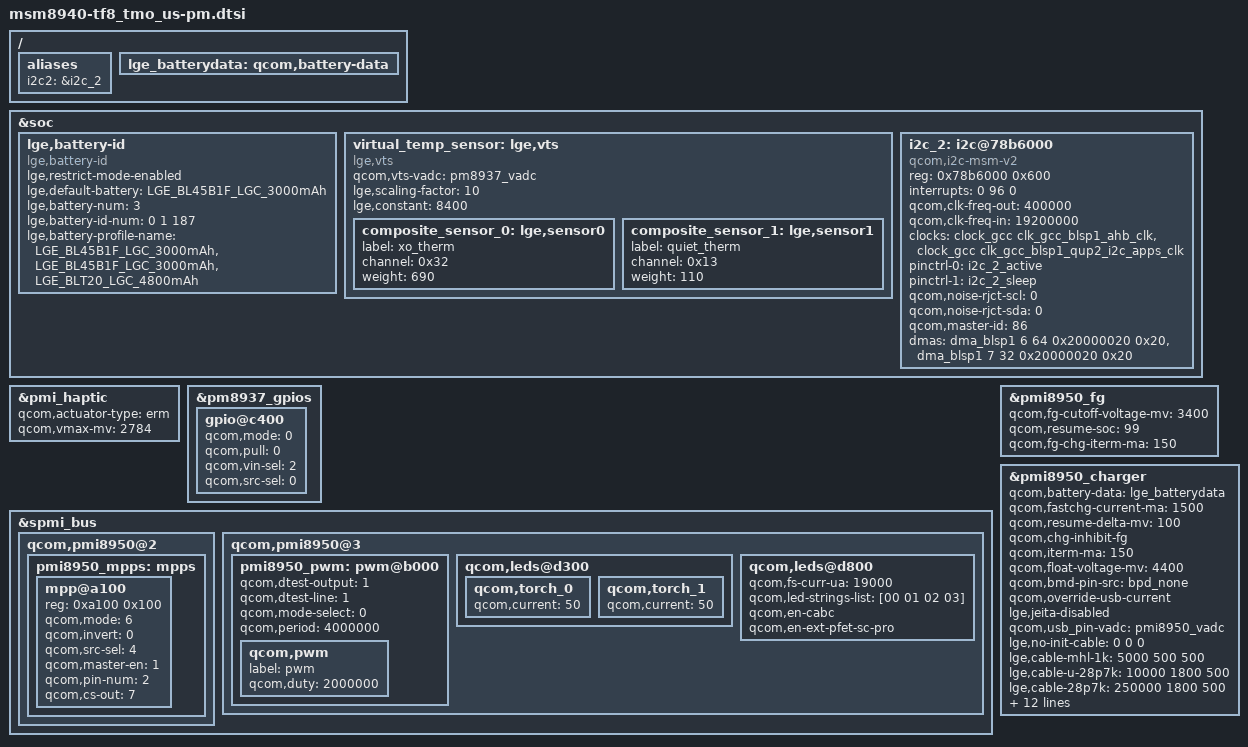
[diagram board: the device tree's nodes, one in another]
/*
 * Copyright (c) 2016, The Linux Foundation. All rights reserved.
 *
 * This program is free software; you can redistribute it and/or modify
 * it under the terms of the GNU General Public License version 2 and
 * only version 2 as published by the Free Software Foundation.
 *
 * This program is distributed in the hope that it will be useful,
 * but WITHOUT ANY WARRANTY; without even the implied warranty of
 * MERCHANTABILITY or FITNESS FOR A PARTICULAR PURPOSE.  See the
 * GNU General Public License for more details.
 */

/ {
	aliases {
		i2c2 = &i2c_2;
	};
};

/{
    lge_batterydata: qcom,battery-data {
         #include "../battery_profile/LGE_BL45B1F_LGC_3000mAh.dtsi"
         #include "../battery_profile/LGE_BLT20_LGC_4800mAh.dtsi"

    };
};

&soc {
	lge,battery-id{
		compatible = "lge,battery-id";
		lge,restrict-mode-enabled;
		/*default battery profile*/
		lge,default-battery = "LGE_BL45B1F_LGC_3000mAh";
		/*Total number of combined of battery cell and battery id */
		lge,battery-num = <3>;
		/* battery id and battery profile match numbers */
		lge,battery-id-num = <0 1 187>;
		/* battery profile */
		lge,battery-profile-name = 	"LGE_BL45B1F_LGC_3000mAh",
						"LGE_BL45B1F_LGC_3000mAh",
						"LGE_BLT20_LGC_4800mAh";
	};

	/* vst = (0.42*xo_therm) + (0.44*quiet_therm) + 4.6 */
	virtual_temp_sensor: lge,vts {
		compatible = "lge,vts";
		qcom,vts-vadc = <&pm8937_vadc>;
		lge,scaling-factor= <10>;
		lge,constant = <8400>;
		composite_sensor_0: lge,sensor0 {
			label = "xo_therm";
			channel = <0x32>;
			weight = <690>;
		};
		composite_sensor_1: lge,sensor1 {
			label = "quiet_therm";
			channel = <0x13>;
			weight = <110>;
		};
	};

	i2c_2: i2c@78b6000 { /* BLSP1 QUP2 */
		compatible = "qcom,i2c-msm-v2";
		#address-cells = <1>;
		#size-cells = <0>;
		reg-names = "qup_phys_addr";
		reg = <0x78b6000 0x600>;
		interrupt-names = "qup_irq";
		interrupts = <0 96 0>;
		qcom,clk-freq-out = <400000>;
		qcom,clk-freq-in  = <19200000>;
		clock-names = "iface_clk", "core_clk";
		clocks = <&clock_gcc clk_gcc_blsp1_ahb_clk>,
			 <&clock_gcc clk_gcc_blsp1_qup2_i2c_apps_clk>;

		pinctrl-names = "i2c_active", "i2c_sleep";
		pinctrl-0 = <&i2c_2_active>;
		pinctrl-1 = <&i2c_2_sleep>;
		qcom,noise-rjct-scl = <0>;
		qcom,noise-rjct-sda = <0>;
		qcom,master-id = <86>;
		dmas = <&dma_blsp1 6 64 0x20000020 0x20>,
			<&dma_blsp1 7 32 0x20000020 0x20>;
		dma-names = "tx", "rx";
	};
};

&pmi_haptic{
	status = "okay";
	qcom,actuator-type = "erm";
	qcom,vmax-mv = <2784>;
};

&pm8937_gpios {
	gpio@c400 {
		qcom,mode = <0>;
		qcom,pull = <0>;
		qcom,vin-sel = <2>;
		qcom,src-sel = <0>;
		status = "okay";
	};
};

&spmi_bus {
	qcom,pmi8950@2 {
		pmi8950_mpps: mpps {
			mpp@a100 {
				status = "okay";
				reg = <0xa100 0x100>;
				qcom,mode = <6>;
				qcom,invert = <0>;
				qcom,src-sel = <4>;
				qcom,master-en = <1>;
				qcom,pin-num = <2>;
				qcom,cs-out = <7>;
			};
		};
	};

	qcom,pmi8950@3 {
		pmi8950_pwm: pwm@b000 {
			status = "ok";
			qcom,dtest-output = <1>;
			qcom,dtest-line = <1>;
			qcom,mode-select = <0>;
			qcom,period = <4000000>;
			qcom,pwm {
				label = "pwm";
				qcom,duty = <2000000>;
			};
		};
		qcom,leds@d300 {
			qcom,torch_0 {
				qcom,current = <50>;
			};
			qcom,torch_1 {
				qcom,current = <50>;
			};
		};
		qcom,leds@d800 {
			qcom,fs-curr-ua = <19000>;
			qcom,led-strings-list = [00 01 02 03];
			qcom,en-cabc;
			qcom,en-ext-pfet-sc-pro;
		};
	};
};

&pmi8950_fg {
	qcom,fg-cutoff-voltage-mv = <3400>;
	qcom,resume-soc = <99>;
	qcom,fg-chg-iterm-ma = <150>;
};

&pmi8950_charger {
	qcom,battery-data = <&lge_batterydata>;
	qcom,fastchg-current-ma = <1500>;
	qcom,resume-delta-mv = <100>;
	qcom,chg-inhibit-fg;
	qcom,iterm-ma = <150>;
	qcom,float-voltage-mv = <4400>;
	qcom,bmd-pin-src = "bpd_none";
	qcom,override-usb-current;
	lge,jeita-disabled;

	qcom,usb_pin-vadc = <&pmi8950_vadc>;

	/* ref resistance 200K */
	lge,no-init-cable = <0 0 0>;
	lge,cable-mhl-1k = <5000 500 500>;
	lge,cable-u-28p7k = <10000 1800 500>;
	lge,cable-28p7k = <250000 1800 500>;
	lge,cable-56k = <600000 1800 1500>;
	lge,cable-100k = <620000 1800 500>;
	lge,cable-130k = <780000 1800 1500>;
	lge,cable-180k = <870000 1800 500>;
	lge,cable-200k = <910000 1800 500>;
	lge,cable-220k = <960000 1800 500>;
	lge,cable-270k = <1050000 1800 500>;
	lge,cable-330k = <1150000 1800 500>;
	lge,cable-620k = <1380000 1800 500>;
	lge,cable-910k = <1630000 1800 1500>;
	lge,cable-none = <1900000 1800  500>;

	lge,usb-max-current-ma = <1800>;
};

